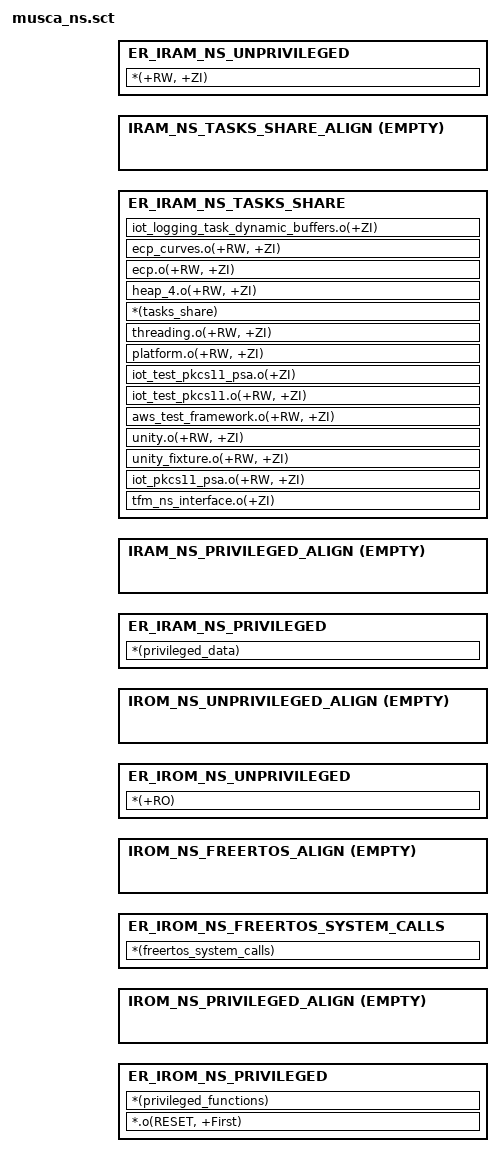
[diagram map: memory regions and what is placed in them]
#! armclang -I ..\..\..\..\..\vendors\arm\boards\musca-b1\aws_tests\application_code\arm_code -DBL2 --target=arm-arm-none-eabi -march=armv8-m.main -E -xc

/*
 * Copyright (c) 2018-2020 ARM Limited
 *
 * Licensed under the Apache License, Version 2.0 (the "License");
 * you may not use this file except in compliance with the License.
 * You may obtain a copy of the License at
 *
 *     http://www.apache.org/licenses/LICENSE-2.0
 *
 * Unless required by applicable law or agreed to in writing, software
 * distributed under the License is distributed on an "AS IS" BASIS,
 * WITHOUT WARRANTIES OR CONDITIONS OF ANY KIND, either express or implied.
 * See the License for the specific language governing permissions and
 * limitations under the License.
 */

/*
 * This file is derivative of TF-M platform/ext/target/musca_b1/Device/Source/armclang/musca_ns.sct
 * (TF-M commit e05b6a65f7235656d96833c069481862f80efd4c)
 */

#include "region_defs.h"

LR_CODE NS_CODE_START ; load region
{
    ER_IROM_NS_PRIVILEGED +0 ALIGN 32
    {
        *.o(RESET, +First)
        *(privileged_functions)
    }

    IROM_NS_PRIVILEGED_ALIGN +0 ALIGN 32 EMPTY 0x0 {
    }

    ER_IROM_NS_FREERTOS_SYSTEM_CALLS +0 ALIGN 32
    {
         *(freertos_system_calls)
    }

    IROM_NS_FREERTOS_ALIGN +0 ALIGN 32 EMPTY 0x0 {
    }

    ER_IROM_NS_UNPRIVILEGED +0 ALIGN 32
    {
         *(+RO)
    }

    IROM_NS_UNPRIVILEGED_ALIGN +0 ALIGN 32 EMPTY 0x0 {
    }

    ER_IRAM_NS_PRIVILEGED NS_DATA_START ALIGN 32
    {
        *(privileged_data)
    }

    IRAM_NS_PRIVILEGED_ALIGN +0 ALIGN 32 EMPTY 0x0 {
    }

    ER_IRAM_NS_TASKS_SHARE +0 ALIGN 32
    {
         tfm_ns_interface.o(+ZI)
         iot_pkcs11_psa.o(+RW, +ZI)
         unity_fixture.o(+RW, +ZI)
         unity.o(+RW, +ZI)
         aws_test_framework.o(+RW, +ZI)
         iot_test_pkcs11.o(+RW, +ZI)
         iot_test_pkcs11_psa.o(+ZI)
         platform.o(+RW, +ZI)
         threading.o(+RW, +ZI)
         *(tasks_share)
         heap_4.o(+RW, +ZI)
         ecp.o(+RW, +ZI)
         ecp_curves.o(+RW, +ZI)
         iot_logging_task_dynamic_buffers.o(+ZI)
    }


    IRAM_NS_TASKS_SHARE_ALIGN +0 ALIGN 32 EMPTY 0x0 {
    }
    ER_IRAM_NS_UNPRIVILEGED +0 ALIGN 32
    {
        *(+RW, +ZI)
    }

}
